# STM32L0x1 register map
File version: 1.6
CPU: CM0+ r0p0, little endian, MPU, no FPU, 2 interrupt priority bits
Registers are 32-bit, read-write, reset 0x0 unless marked. A register's access mark holds for its fields unless they carry their own. Offsets are from the block's base; [hi:lo] are bit positions; {n}, {i} and the like mark numbered series; 'fields as' and 'values as' point back to an identical list.

## RTC — Real-time clock
Base 0x40002800
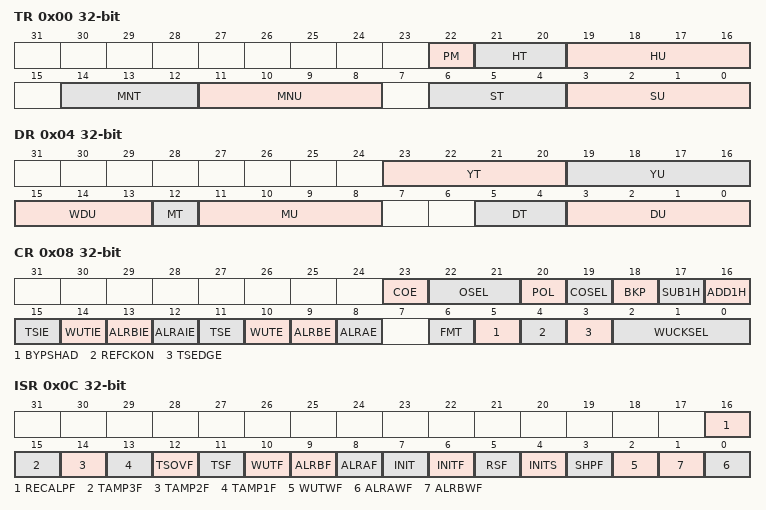
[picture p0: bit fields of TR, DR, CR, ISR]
0x00 TR — RTC time register
  [22] PM — AM/PM notation
    0=AM (AM or 24-hour format); 1=PM
  [21:20] HT — Hour tens in BCD format
  [19:16] HU — Hour units in BCD format
  [14:12] MNT — Minute tens in BCD format
  [11:8] MNU — Minute units in BCD format
  [6:4] ST — Second tens in BCD format
  [3:0] SU — Second units in BCD format
0x04 DR — RTC date register
  [23:20] YT — Year tens in BCD format
  [19:16] YU — Year units in BCD format
  [15:13] WDU range 1..7 — Week day units
  [12] MT — Month tens in BCD format
    0=Zero (Month tens is 0); 1=One (Month tens is 1)
  [11:8] MU — Month units in BCD format
  [5:4] DT — Date tens in BCD format
  [3:0] DU — Date units in BCD format
0x08 CR access per field — RTC control register
  [23] COE rw — Calibration output enable
    0=Disabled (Calibration output disabled); 1=Enabled (Calibration output enabled)
  [22:21] OSEL rw — Output selection
    0=Disabled (Output disabled); 1=Alarm A output enabled; 2=Alarm B output enabled; 3=Wakeup output enabled
  [20] POL rw — Output polarity
    0=High (The pin is high when ALRAF/ALRBF/WUTF is asserted (depending on OSEL[1:0])); 1=Low (The pin is low when ALRAF/ALRBF/WUTF is asserted (depending on OSEL[1:0]))
  [19] COSEL rw — Calibration output selection
    0=CalFreq_512Hz (Calibration output is 512 Hz (with default prescaler setting)); 1=CalFreq_1Hz (Calibration output is 1 Hz (with default prescaler setting))
  [18] BKP rw — Backup
    0=DST_Not_Changed (Daylight Saving Time change has not been performed); 1=DST_Changed (Daylight Saving Time change has been performed)
  [17] SUB1H wo — Subtract 1 hour (winter time change)
    1=Sub1 (Subtracts 1 hour to the current time. This can be used for winter time change outside initialization mode)
  [16] ADD1H wo — Add 1 hour (summer time change)
    1=Add1 (Adds 1 hour to the current time. This can be used for summer time change outside initialization mode)
  [15] TSIE rw — Time-stamp interrupt enable
    0=Disabled (Time-stamp Interrupt disabled); 1=Enabled (Time-stamp Interrupt enabled)
  [14] WUTIE rw — Wakeup timer interrupt enable
    0=Disabled (Wakeup timer interrupt disabled); 1=Enabled (Wakeup timer interrupt enabled)
  [12] ALR{x}IE (x=A,B; step 1) rw — Alarm {x} interrupt enable
    0=Disabled (Alarm Interrupt disabled); 1=Enabled (Alarm Interrupt enabled)
  [11] TSE rw — timestamp enable
    0=Disabled (Timestamp disabled); 1=Enabled (Timestamp enabled)
  [10] WUTE rw — Wakeup timer enable
    0=Disabled (Wakeup timer disabled); 1=Enabled (Wakeup timer enabled)
  [8] ALR{x}E (x=A,B; step 1) rw — Alarm {x} enable
    0=Disabled (Alarm disabled); 1=Enabled (Alarm enabled)
  [6] FMT rw — Hour format
    0=Twenty_Four_Hour (24 hour/day format); 1=AM_PM (AM/PM hour format)
  [5] BYPSHAD rw — Bypass the shadow registers
    0=ShadowReg (Calendar values (when reading from RTC_SSR, RTC_TR, and RTC_DR) are taken from the shadow registers, which are updated once every two RTCCLK cycles); 1=BypassShadowReg (Calendar values (when reading from RTC_SSR, RTC_TR, and RTC_DR) are taken directly from the calendar counters)
  [4] REFCKON rw — RTC_REFIN reference clock detection enable (50 or 60 Hz)
    0=Disabled (RTC_REFIN detection disabled); 1=Enabled (RTC_REFIN detection enabled)
  [3] TSEDGE rw — Time-stamp event active edge
    0=RisingEdge (RTC_TS input rising edge generates a time-stamp event); 1=FallingEdge (RTC_TS input falling edge generates a time-stamp event)
  [2:0] WUCKSEL rw — Wakeup clock selection
    0=Div16 (RTC/16 clock is selected); 1=Div8 (RTC/8 clock is selected); 2=Div4 (RTC/4 clock is selected); 3=Div2 (RTC/2 clock is selected); 4=ClockSpare (ck_spre (usually 1 Hz) clock is selected); 6=ClockSpareWithOffset (ck_spre (usually 1 Hz) clock is selected and 2^16 is added to the WUT counter value)
0x0C ISR access not given — RTC initialization and status register
  [16] RECALPF — Recalibration pending flag
    on read: 1=Pending (The RECALPF status flag is automatically set to 1 when software writes to the RTC_CALR register, indicating that the RTC_CALR register is blocked. When the new calibration settings are taken into account, this bit returns to 0)
  [15] TAMP3F write-0-clears — RTC_TAMP3 detection flag
    on read: 1=Tampered (This flag is set by hardware when a tamper detection event is detected on the RTC_TAMPx input) | on write: 0=Clear (Flag cleared by software writing 0)
  [14] TAMP2F rw write-0-clears — RTC_TAMP2 detection flag
    values as TAMP3F
  [13] TAMP1F rw write-0-clears — RTC_TAMP1 detection flag
    values as TAMP3F
  [12] TSOVF rw write-0-clears — Time-stamp overflow flag
    on read: 1=Overflow (This flag is set by hardware when a time-stamp event occurs while TSF is already set) | on write: 0=Clear (This flag is cleared by software by writing 0)
  [11] TSF rw write-0-clears — Time-stamp flag
    on read: 1=TimestampEvent (This flag is set by hardware when a time-stamp event occurs) | on write: 0=Clear (This flag is cleared by software by writing 0)
  [10] WUTF rw write-0-clears — Wakeup timer flag
    on read: 1=Zero (This flag is set by hardware when the wakeup auto-reload counter reaches 0) | on write: 0=Clear (This flag is cleared by software by writing 0)
  [8] ALR{x}F (x=A,B; step 1) rw write-0-clears — Alarm {x} flag
    on read: 1=Match (This flag is set by hardware when the time/date registers (RTC_TR and RTC_DR) match the Alarm register (RTC_ALRMxR)) | on write: 0=Clear (This flag is cleared by software by writing 0)
  [7] INIT rw — Initialization mode
    0=FreeRunningMode; 1=InitMode (Initialization mode used to program time and date register (RTC_TR and RTC_DR), and prescaler register (RTC_PRER). Counters are stopped and start counting from the new value when INIT is reset.)
  [6] INITF ro — Initialization flag
    0=NotAllowed (Calendar registers update is not allowed); 1=Allowed (Calendar registers update is allowed)
  [5] RSF rw write-0-clears — Registers synchronization flag
    on read: 0=NotSynced (Calendar shadow registers not yet synchronized); 1=Synced (Calendar shadow registers synchronized) | on write: 0=Clear (This flag is cleared by software by writing 0)
  [4] INITS ro — Initialization status flag
    0=NotInitalized (Calendar has not been initialized); 1=Initalized (Calendar has been initialized)
  [3] SHPF ro — Shift operation pending
    0=NoShiftPending (No shift operation is pending); 1=ShiftPending (A shift operation is pending)
  [2] WUTWF ro — Wakeup timer write flag
    0=UpdateNotAllowed (Wakeup timer configuration update not allowed); 1=UpdateAllowed (Wakeup timer configuration update allowed)
  [0] ALR{x}WF (x=A,B; step 1) ro — Alarm {x} write flag
    0=UpdateNotAllowed (Alarm update not allowed); 1=UpdateAllowed (Alarm update allowed)
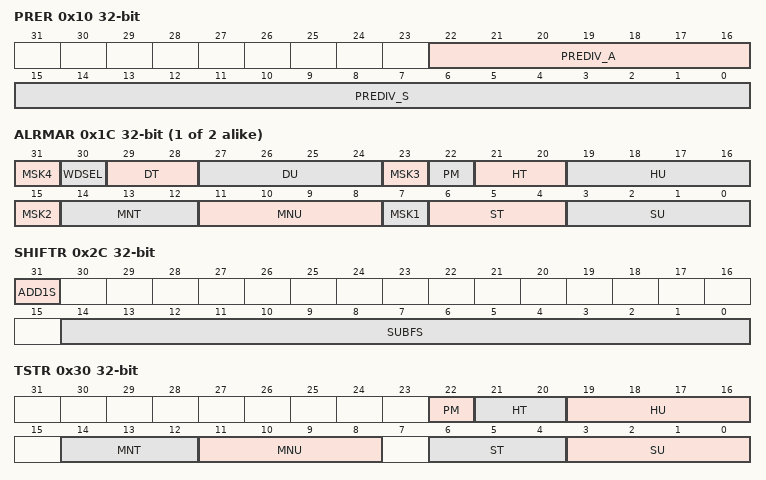
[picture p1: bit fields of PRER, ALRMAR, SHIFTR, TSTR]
0x10 PRER — RTC prescaler register
  [22:16] PREDIV_A — Asynchronous prescaler factor
  [15:0] PREDIV_S range 0..32767 — Synchronous prescaler factor
0x14 WUTR — RTC wakeup timer register
  [15:0] WUT — Wakeup auto-reload value bits
0x1C ALRM{x}R (x=A,B; step 0x4) — Alarm {x} register
  [31] MSK4 — Alarm date mask
    0=Mask (Alarm set if the date/day match); 1=NotMask (Date/day don’t care in Alarm comparison)
  [30] WDSEL — Week day selection
    0=DateUnits (DU[3:0] represents the date units); 1=WeekDay (DU[3:0] represents the week day. DT[1:0] is don’t care.)
  [29:28] DT — Date tens in BCD format
  [27:24] DU — Date units or day in BCD format
  [23] MSK3 — Alarm hours mask
    values as MSK4
  [22] PM — AM/PM notation
    0=AM (AM or 24-hour format); 1=PM
  [21:20] HT — Hour tens in BCD format
  [19:16] HU — Hour units in BCD format
  [15] MSK2 — Alarm minutes mask
    values as MSK4
  [14:12] MNT — Minute tens in BCD format
  [11:8] MNU — Minute units in BCD format
  [7] MSK1 — Alarm seconds mask
    values as MSK4
  [6:4] ST — Second tens in BCD format
  [3:0] SU — Second units in BCD format
0x24 WPR wo — write protection register
  [7:0] KEY — Write protection key
0x28 SSR ro — RTC sub second register
  [15:0] SS — Sub second value
0x2C SHIFTR wo — RTC shift control register
  [31] ADD1S — Add one second
    1=Add1 (Add one second to the clock/calendar)
  [14:0] SUBFS — Subtract a fraction of a second
0x30 TSTR — RTC timestamp time register
  fields as TR
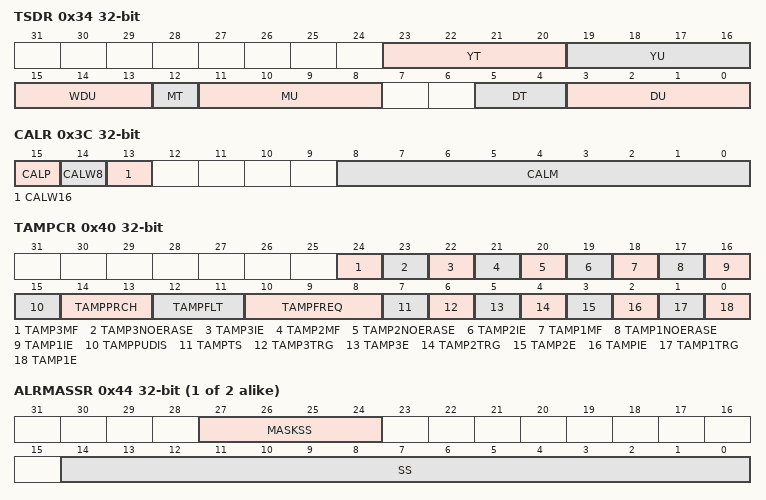
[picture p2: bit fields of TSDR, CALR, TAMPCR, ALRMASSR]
0x34 TSDR — RTC timestamp date register
  fields as DR
0x38 TSSSR ro — RTC time-stamp sub second register
  [15:0] SS — Sub second value
0x3C CALR — RTC calibration register
  [15] CALP — Increase frequency of RTC by 488.5 ppm
    0=NoChange (No RTCCLK pulses are added); 1=IncreaseFreq (One RTCCLK pulse is effectively inserted every 2^11 pulses (frequency increased by 488.5 ppm))
  [14] CALW8 — Use an 8-second calibration cycle period
    1=Eight_Second (When CALW8 is set to ‘1’, the 8-second calibration cycle period is selected)
  [13] CALW16 — Use a 16-second calibration cycle period
    1=Sixteen_Second (When CALW16 is set to ‘1’, the 16-second calibration cycle period is selected.This bit must not be set to ‘1’ if CALW8=1)
  [8:0] CALM — Calibration minus
0x40 TAMPCR — RTC tamper configuration register
  [24] TAMP3MF — Tamper 3 mask flag
    0=NotMasked (Tamper x event generates a trigger event and TAMPxF must be cleared by software to allow next tamper event detection); 1=Masked (Tamper x event generates a trigger event. TAMPxF is masked and internally cleared by hardware. The backup registers are not erased.)
  [23] TAMP3NOERASE — Tamper 3 no erase
    0=Erase (Tamper x event erases the backup registers); 1=NoErase (Tamper x event does not erase the backup registers)
  [22] TAMP3IE — Tamper 3 interrupt enable
    0=Disabled (Tamper x interrupt is disabled if TAMPIE = 0); 1=Enabled (Tamper x interrupt enabled)
  [21] TAMP2MF — Tamper 2 mask flag
    values as TAMP3MF
  [20] TAMP2NOERASE — Tamper 2 no erase
    values as TAMP3NOERASE
  [19] TAMP2IE — Tamper 2 interrupt enable
    values as TAMP3IE
  [18] TAMP1MF — Tamper 1 mask flag
    values as TAMP3MF
  [17] TAMP1NOERASE — Tamper 1 no erase
    values as TAMP3NOERASE
  [16] TAMP1IE — Tamper 1 interrupt enable
    values as TAMP3IE
  [15] TAMPPUDIS — RTC_TAMPx pull-up disable
    0=Enabled (Precharge RTC_TAMPx pins before sampling (enable internal pull-up)); 1=Disabled (Disable precharge of RTC_TAMPx pins)
  [14:13] TAMPPRCH — RTC_TAMPx precharge duration
    0=Cycles1 (1 RTCCLK cycle); 1=Cycles2 (2 RTCCLK cycles); 2=Cycles4 (4 RTCCLK cycles); 3=Cycles8 (8 RTCCLK cycles)
  [12:11] TAMPFLT — RTC_TAMPx filter count
    0=Immediate (Tamper event is activated on edge of RTC_TAMPx input transitions to the active level (no internal pull-up on RTC_TAMPx input)); 1=Samples2 (Tamper event is activated after 2 consecutive samples at the active level); 2=Samples4 (Tamper event is activated after 4 consecutive samples at the active level); 3=Samples8 (Tamper event is activated after 8 consecutive samples at the active level)
  [10:8] TAMPFREQ — Tamper sampling frequency
    0=Div32768 (RTCCLK / 32768 (1 Hz when RTCCLK = 32768 Hz)); 1=Div16384 (RTCCLK / 16384 (2 Hz when RTCCLK = 32768 Hz)); 2=Div8192 (RTCCLK / 8192 (4 Hz when RTCCLK = 32768 Hz)); 3=Div4096 (RTCCLK / 4096 (8 Hz when RTCCLK = 32768 Hz)); 4=Div2048 (RTCCLK / 2048 (16 Hz when RTCCLK = 32768 Hz)); 5=Div1024 (RTCCLK / 1024 (32 Hz when RTCCLK = 32768 Hz)); 6=Div512 (RTCCLK / 512 (64 Hz when RTCCLK = 32768 Hz)); 7=Div256 (RTCCLK / 256 (128 Hz when RTCCLK = 32768 Hz))
  [7] TAMPTS — Activate timestamp on tamper detection event
    0=NoSave (Tamper detection event does not cause a timestamp to be saved); 1=Save timestamp on tamper detection event
  [6] TAMP3TRG — Active level for RTC_TAMP3 input
    0=RisingEdge (If TAMPFLT = 00: RTC_TAMPx input rising edge triggers a tamper detection event. If TAMPFLT ≠ 00: RTC_TAMPx input staying low triggers a tamper detection event.); 1=FallingEdge (If TAMPFLT = 00: RTC_TAMPx input staying high triggers a tamper detection event. If TAMPFLT ≠ 00: RTC_TAMPx input falling edge triggers a tamper detection event)
  [5] TAMP3E — RTC_TAMP3 detection enable
    0=Disabled (RTC_TAMPx input detection disabled); 1=Enabled (RTC_TAMPx input detection enabled)
  [4] TAMP2TRG — Active level for RTC_TAMP2 input
    values as TAMP3TRG
  [3] TAMP2E — RTC_TAMP2 input detection enable
    values as TAMP3E
  [2] TAMPIE — Tamper interrupt enable
    0=Disabled (Tamper interrupt disabled); 1=Enabled (Tamper interrupt enabled)
  [1] TAMP1TRG — Active level for RTC_TAMP1 input
    values as TAMP3TRG
  [0] TAMP1E — RTC_TAMP1 input detection enable
    values as TAMP3E
0x44 ALRM{x}SSR (x=A,B; step 0x4) — Alarm {x} sub-second register
  [27:24] MASKSS — Mask the most-significant bits starting at this bit
  [14:0] SS — Sub seconds value
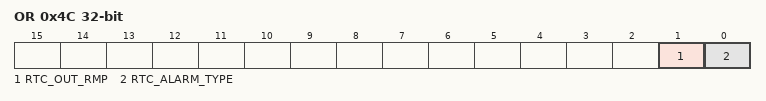
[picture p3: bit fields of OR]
0x4C OR — option register
  [1] RTC_OUT_RMP — RTC_ALARM on PC13 output type
  [0] RTC_ALARM_TYPE — RTC_ALARM on PC13 output type
{0x50+4i} BKP{i}R (i=0..4) — RTC backup registers
  [31:0] BKP
